# ESP32-H21 register map
Vendor: ESPRESSIF SYSTEMS (SHANGHAI) CO., LTD.; Series: ESP32 H-Series; File version: 1
CPU: RV32IMAC r0p0, little endian, no MPU, no FPU, 0 interrupt priority bits
Address unit: 32 bits
Registers are 32-bit, read-write, reset 0x0 unless marked. A register's access mark holds for its fields unless they carry their own. Offsets are from the block's base; [hi:lo] are bit positions; {n}, {i} and the like mark numbered series.

## ECDSA — ECDSA (Elliptic Curve Digital Signature Algorithm) Accelerator
Base 0x6008E000
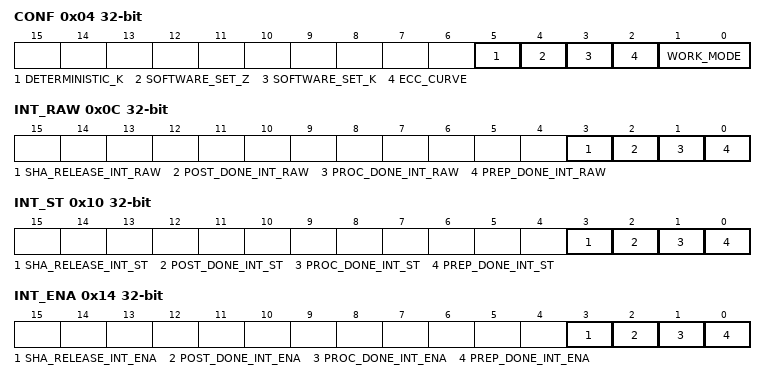
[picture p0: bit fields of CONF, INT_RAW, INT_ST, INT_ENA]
0x04 CONF — ECDSA configuration register
  [5] DETERMINISTIC_K — Configures how the parameter 5$ is set. \\ 0: Automatically generated by TRNG\\ 1: Generated by the deterministic derivation algorithm\\
  [4] SOFTWARE_SET_Z — Configures how the parameter 4$ is set. \\ 0: Generated from SHA result\\ 1: Written by software\\
  [3] SOFTWARE_SET_K — Configures the generation source of k.\\ 0: k is automatically generated by hardware\\ 1: k is written by software\\
  [2] ECC_CURVE — Configures the elliptic curve used.\\ 0: P-192\\ 1: P-256\\
  [1:0] WORK_MODE — Configures the working mode of ECDSA accelerator. \\ 0: Signature Verification Mode\\ 1: Signature Generation Mode\\ 2: Public Key Export Mode\\ 3: Invalid\\
0x08 CLK — ECDSA clock gate register
  [0] GATE_FORCE_ON — Configures whether to force on ECDSA memory clock gate. \\ 0: No effect\\ 1: Force on\\
0x0C INT_RAW ro — ECDSA interrupt raw register
  [3] SHA_RELEASE_INT_RAW — The raw interrupt status of the ECDSA_SHA_RELEASE_INT interrupt.
  [2] POST_DONE_INT_RAW — The raw interrupt status of the ECDSA_POST_DONE_INT interrupt.
  [1] PROC_DONE_INT_RAW — The raw interrupt status of the ECDSA_PROC_DONE_INT interrupt.
  [0] PREP_DONE_INT_RAW — The raw interrupt status of the ECDSA_PREP_DONE_INT interrupt.
0x10 INT_ST ro — ECDSA interrupt status register
  [3] SHA_RELEASE_INT_ST — The masked interrupt status of the ECDSA_SHA_RELEASE_INT interrupt.
  [2] POST_DONE_INT_ST — The masked interrupt status of the ECDSA_POST_DONE_INT interrupt.
  [1] PROC_DONE_INT_ST — The masked interrupt status of the ECDSA_PROC_DONE_INT interrupt.
  [0] PREP_DONE_INT_ST — The masked interrupt status of the ECDSA_PREP_DONE_INT interrupt.
0x14 INT_ENA — ECDSA interrupt enable register
  [3] SHA_RELEASE_INT_ENA — Write 1 to enable the ECDSA_SHA_RELEASE_INT interrupt.
  [2] POST_DONE_INT_ENA — Write 1 to enable the ECDSA_POST_DONE_INT interrupt.
  [1] PROC_DONE_INT_ENA — Write 1 to enable the ECDSA_PROC_DONE_INT interrupt.
  [0] PREP_DONE_INT_ENA — Write 1 to enable the ECDSA_PREP_DONE_INT interrupt.
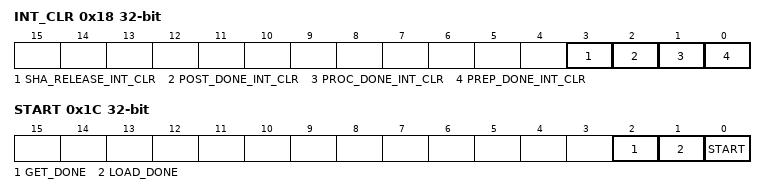
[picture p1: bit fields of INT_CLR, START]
0x18 INT_CLR wo — ECDSA interrupt clear register
  [3] SHA_RELEASE_INT_CLR — Write 1 to clear the ECDSA_SHA_RELEASE_INT interrupt.
  [2] POST_DONE_INT_CLR — Write 1 to clear the ECDSA_POST_DONE_INT interrupt.
  [1] PROC_DONE_INT_CLR — Write 1 to clear the ECDSA_PROC_DONE_INT interrupt.
  [0] PREP_DONE_INT_CLR — Write 1 to clear the ECDSA_PREP_DONE_INT interrupt.
0x1C START wo — ECDSA start register
  [2] GET_DONE — Write 1 to generate a signal indicating the ECDSA accelerator's GAIN operation is done. This bit will be self-cleared after configuration.
  [1] LOAD_DONE — Write 1 to generate a signal indicating the ECDSA accelerator's LOAD operation is done. This bit will be self-cleared after configuration.
  [0] START — Configures whether to start the ECDSA operation. This bit will be self-cleared after configuration. \\ 0: No effect\\ 1: Start the ECDSA operation\\
0x20 STATE ro — ECDSA status register
  [1:0] BUSY — Represents the working status of the ECDSA accelerator.\\ 0: IDLE\\ 1: LOAD\\ 2: GAIN\\ 3: BUSY\\
0x24 RESULT ro — ECDSA result register
  [0] OPERATION_RESULT — Indicates if the ECDSA operation is successful.\\ 0: Not successful\\ 1: Successful\\ Only valid when the ECDSA operation is done. \\
0xFC DATE reset 0x2403120 — Version control register
  [27:0] DATE — The ECDSA version control register.
0x200 SHA_MODE — ECDSA SHA-control register (Hash algrithm)
  [2:0] SHA_MODE — Configures SHA algorithms for message hash. \\ 1: SHA-224\\ 2: SHA-256\\ Others: invalid\\
0x210 SHA_START wo — ECDSA SHA-control register (operation)
  [0] SHA_START — Write 1 to start the first SHA operation in the ECDSA process. This bit will be self-cleared after configuration.
0x214 SHA_CONTINUE wo — ECDSA SHA-control register (operation)
  [0] SHA_CONTINUE — Write 1 to start the latter SHA operation in the ECDSA process. This bit will be self-cleared after configuration.
0x218 SHA_BUSY ro — ECDSA SHA-control status register
  [0] SHA_BUSY — Represents the working status of the SHA accelerator in the ECDSA process.\\ 0: IDLE\\ 1: BUSY\\
{0x280+i} MESSAGE_MEM[{i}] (i=0..31) 8-bit access not given — The memory that stores message.
{0x340+i} R_MEM[{i}] (i=0..31) 8-bit access not given — The memory that stores r.
{0x360+i} S_MEM[{i}] (i=0..31) 8-bit access not given — The memory that stores s.
{0x380+i} Z_MEM[{i}] (i=0..31) 8-bit access not given — The memory that stores software written z.
{0x3A0+i} QAX_MEM[{i}] (i=0..31) 8-bit access not given — The memory that stores x coordinates of QA or software written k.
{0x3C0+i} QAY_MEM[{i}] (i=0..31) 8-bit access not given — The memory that stores y coordinates of QA.
